VERSION ""

NS_ :

BS_:
BU_: OBC
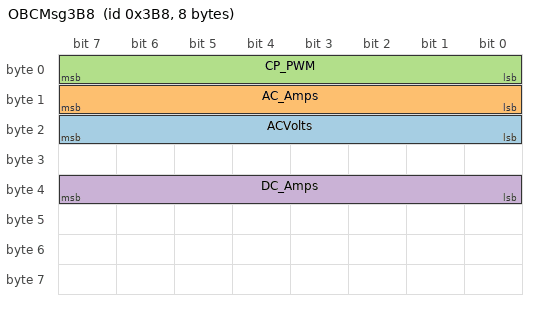
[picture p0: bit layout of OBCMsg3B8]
BO_ 952 OBCMsg3B8: 8 OBC
   SG_ ACVolts : 23|8@0+ (2,0) [0|255] "Volts" Vector__XXX
   SG_ AC_Amps : 15|8@0+ (0.25,0) [0|35] "" Vector__XXX
   SG_ CP_PWM : 0|8@1+ (1,0) [0|0] "" Vector__XXX
   SG_ DC_Amps : 32|8@1+ (0.05,0) [0|50] "Amps" Vector__XXX

BA_DEF_ BO_ "GenMsgBackgroundColor" STRING ;
BA_DEF_ BO_ "GenMsgForegroundColor" STRING ;
BA_DEF_ BO_ "filterlabeling" INT 0 0;
BA_DEF_DEF_ "GenMsgBackgroundColor" "#ffffff";
BA_DEF_DEF_ "GenMsgForegroundColor" "#000000";
BA_DEF_DEF_ "filterlabeling" 1;
VAL_ 952 CP_PWM 100 "Static_Pilot";
